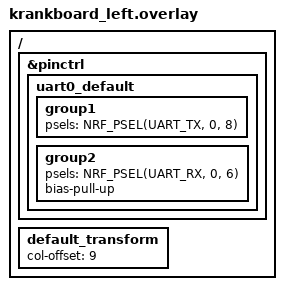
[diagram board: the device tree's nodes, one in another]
#include "krankboard.dtsi" // The shared dtsi file is included in the overlay
#include <dt-bindings/zmk/matrix_transform.h>

/{

	//Label of the kscan node in the dtsi
	//kscan0 {
	//	col-gpios = <&pro_micro 2 GPIO_ACTIVE_LOW>,
	//				<&pro_micro 3 GPIO_ACTIVE_LOW>,
	//				<&pro_micro 4 GPIO_ACTIVE_LOW>,
	//				<&pro_micro 5 GPIO_ACTIVE_LOW>,
	//				<&pro_micro 6 GPIO_ACTIVE_LOW>,
	//				<&pro_micro 7 GPIO_ACTIVE_LOW>,
	//				<&pro_micro 8 GPIO_ACTIVE_LOW>,
	//				<&pro_micro 9 GPIO_ACTIVE_LOW>,
	//				<&pro_micro 10 GPIO_ACTIVE_LOW>;
	//};
	
	&pinctrl {
	/* configuration for uart0 device, default state */
	uart0_default: uart0_default {
			group1 {
				psels = <NRF_PSEL(UART_TX, 0, 8)>;
			};
			group2 {
				psels = <NRF_PSEL(UART_RX, 0, 6)>;
				bias-pull-up;
			};
		};
	
	};

	default_transform { 
		col-offset = <9>;
	};

};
